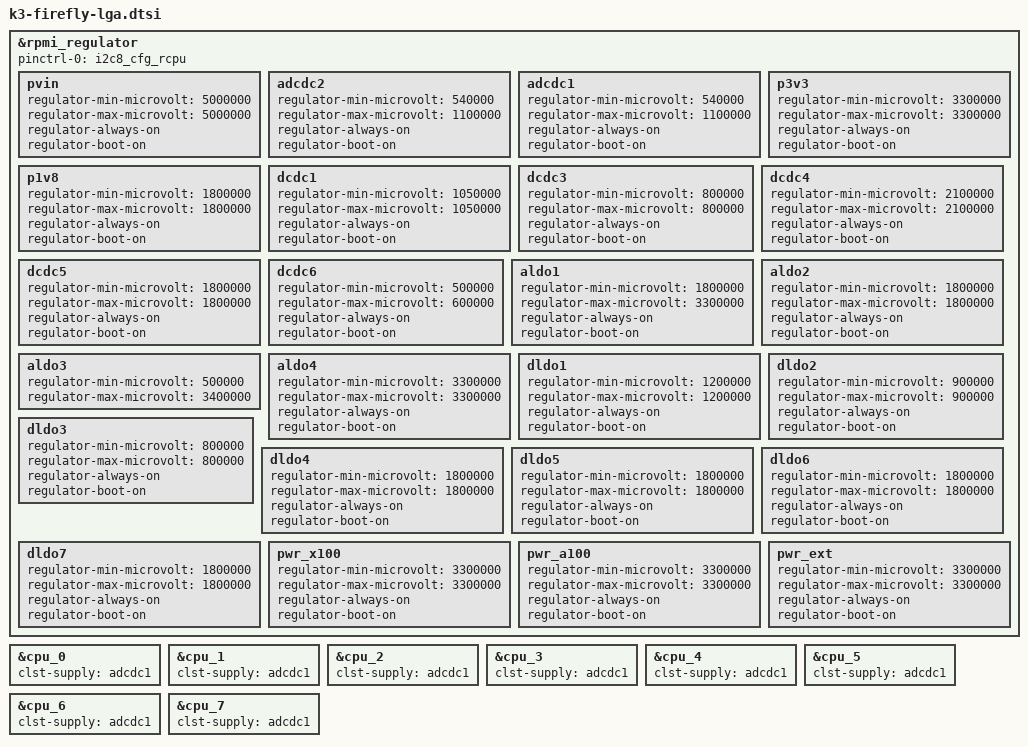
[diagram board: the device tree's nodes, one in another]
&rpmi_regulator {
	status = "okay";
	pinctrl-names = "default";
	pinctrl-0 = <&i2c8_cfg_rcpu>;

	pvin: pvin {
		regulator-min-microvolt = <5000000>;
		regulator-max-microvolt = <5000000>;
		regulator-always-on;
		regulator-boot-on;
	};

	adcdc2: adcdc2 {
		regulator-min-microvolt = <540000>;
		regulator-max-microvolt = <1100000>;
		regulator-always-on;
		regulator-boot-on;
	};

	adcdc1: adcdc1 {
		regulator-min-microvolt = <540000>;
		regulator-max-microvolt = <1100000>;
		regulator-always-on;
		regulator-boot-on;
	};

	p3v3: p3v3 {
		regulator-min-microvolt = <3300000>;
		regulator-max-microvolt = <3300000>;
		regulator-always-on;
		regulator-boot-on;
	};

	p1v8: p1v8 {
		regulator-min-microvolt = <1800000>;
		regulator-max-microvolt = <1800000>;
		regulator-always-on;
		regulator-boot-on;
	};

	dcdc1: dcdc1 {
		regulator-min-microvolt = <1050000>;
		regulator-max-microvolt = <1050000>;
		regulator-always-on;
		regulator-boot-on;
	};

	dcdc3: dcdc3 {
		regulator-min-microvolt = <800000>;
		regulator-max-microvolt = <800000>;
		regulator-always-on;
		regulator-boot-on;
	};

	dcdc4: dcdc4 {
		regulator-min-microvolt = <2100000>;
		regulator-max-microvolt = <2100000>;
		regulator-always-on;
		regulator-boot-on;
	};

	dcdc5: dcdc5 {
		regulator-min-microvolt = <1800000>;
		regulator-max-microvolt = <1800000>;
		regulator-always-on;
		regulator-boot-on;
	};

	dcdc6: dcdc6 {
		regulator-min-microvolt = <500000>;
		regulator-max-microvolt = <600000>;
		regulator-always-on;
		regulator-boot-on;
	};

	aldo1: aldo1 {
		regulator-min-microvolt = <1800000>;
		regulator-max-microvolt = <3300000>;
		regulator-always-on;
		regulator-boot-on;
	};

	aldo2: aldo2 {
		regulator-min-microvolt = <1800000>;
		regulator-max-microvolt = <1800000>;
		regulator-always-on;
		regulator-boot-on;
	};

	aldo3: aldo3 {
		regulator-min-microvolt = <500000>;
		regulator-max-microvolt = <3400000>;
	};

	aldo4: aldo4 {
		regulator-min-microvolt = <3300000>;
		regulator-max-microvolt = <3300000>;
		regulator-always-on;
		regulator-boot-on;
	};

	dldo1: dldo1 {
		regulator-min-microvolt = <1200000>;
		regulator-max-microvolt = <1200000>;
		regulator-always-on;
		regulator-boot-on;
	};

	dldo2: dldo2 {
		regulator-min-microvolt = <900000>;
		regulator-max-microvolt = <900000>;
		regulator-always-on;
		regulator-boot-on;
	};

	dldo3: dldo3 {
		regulator-min-microvolt = <800000>;
		regulator-max-microvolt = <800000>;
		regulator-always-on;
		regulator-boot-on;
	};

	dldo4: dldo4 {
		regulator-min-microvolt = <1800000>;
		regulator-max-microvolt = <1800000>;
		regulator-always-on;
		regulator-boot-on;
	};

	dldo5: dldo5 {
		regulator-min-microvolt = <1800000>;
		regulator-max-microvolt = <1800000>;
		regulator-always-on;
		regulator-boot-on;
	};

	dldo6: dldo6 {
		regulator-min-microvolt = <1800000>;
		regulator-max-microvolt = <1800000>;
		regulator-always-on;
		regulator-boot-on;
	};

	dldo7: dldo7 {
		regulator-min-microvolt = <1800000>;
		regulator-max-microvolt = <1800000>;
		regulator-always-on;
		regulator-boot-on;
	};

	pwr_x100: pwr_x100 {
		regulator-min-microvolt = <3300000>;
		regulator-max-microvolt = <3300000>;
		regulator-always-on;
		regulator-boot-on;
	};

	pwr_a100: pwr_a100 {
		regulator-min-microvolt = <3300000>;
		regulator-max-microvolt = <3300000>;
		regulator-always-on;
		regulator-boot-on;
	};

	pwr_ext: pwr_ext {
		regulator-min-microvolt = <3300000>;
		regulator-max-microvolt = <3300000>;
		regulator-always-on;
		regulator-boot-on;
	};
};

&cpu_0 {
	clst-supply = <&adcdc1>;
};

&cpu_1 {
	clst-supply = <&adcdc1>;
};

&cpu_2 {
	clst-supply = <&adcdc1>;
};

&cpu_3 {
	clst-supply = <&adcdc1>;
};

&cpu_4 {
	clst-supply = <&adcdc1>;
};

&cpu_5 {
	clst-supply = <&adcdc1>;
};

&cpu_6 {
	clst-supply = <&adcdc1>;
};

&cpu_7 {
	clst-supply = <&adcdc1>;
};
